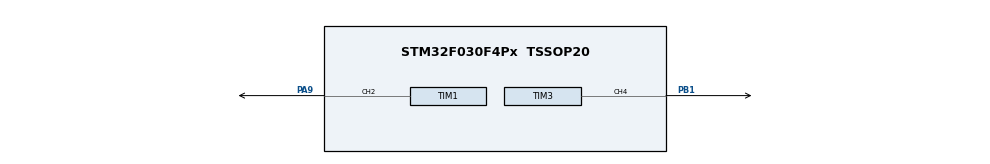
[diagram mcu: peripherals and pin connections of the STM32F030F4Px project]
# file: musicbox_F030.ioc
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Mcu.Family=STM32F0
Mcu.Name=STM32F030F4Px
Mcu.Package=TSSOP20
PA9.Signal=S_TIM1_CH2
PB1.Signal=S_TIM3_CH4
ProjectManager.HeapSize=0x200
ProjectManager.StackSize=0x400
ProjectManager.TargetToolchain=STM32CubeIDE
SH.S_TIM1_CH2.0=TIM1_CH2,PWM Generation2 CH2
SH.S_TIM3_CH4.0=TIM3_CH4,PWM Generation4 CH4
TIM1.Channel-PWM\ Generation2\ CH2=TIM_CHANNEL_2
TIM1.Period=2271
TIM1.Prescaler=7
TIM1.Pulse-PWM\ Generation2\ CH2=1136
TIM3.Channel-PWM\ Generation4\ CH4=TIM_CHANNEL_4
TIM3.Period=2271
TIM3.Prescaler=7
TIM3.Pulse-PWM\ Generation4\ CH4=1136
board=custom

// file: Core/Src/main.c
/* USER CODE BEGIN Header */
/**
  ******************************************************************************
  * @file           : main.c
  * @brief          : Main program body
  ******************************************************************************
  * @attention
  *
  * <h2><center>&copy; Copyright (c) 2021 STMicroelectronics.
  * All rights reserved.</center></h2>
  *
  * This software component is licensed by ST under BSD 3-Clause license,
  * the "License"; You may not use this file except in compliance with the
  * License. You may obtain a copy of the License at:
  *                        opensource.org/licenses/BSD-3-Clause
  *
  ******************************************************************************
  */
/* USER CODE END Header */
#include "main.h"

/* USER CODE BEGIN Includes */
#include <musicbox.hpp>
/* USER CODE END Includes */

TIM_HandleTypeDef htim1;
TIM_HandleTypeDef htim3;

void SystemClock_Config(void);
static void MX_GPIO_Init(void);
static void MX_TIM1_Init(void);
static void MX_TIM3_Init(void);

int main(void)
{

  /* MCU Configuration--------------------------------------------------------*/

  /* Reset of all peripherals, Initializes the Flash interface and the Systick. */
  HAL_Init();

  /* Configure the system clock */
  SystemClock_Config();

  /* Initialize all configured peripherals */
  MX_GPIO_Init();
  MX_TIM1_Init();
  MX_TIM3_Init();
  /* USER CODE BEGIN 2 */
  startMusic(&htim1, TIM_CHANNEL_2, &htim3, TIM_CHANNEL_4);
  /* USER CODE END 2 */

  /* Infinite loop */
  while (1)
  {

  }
}

void SystemClock_Config(void)
{
  RCC_OscInitTypeDef RCC_OscInitStruct = {0};
  RCC_ClkInitTypeDef RCC_ClkInitStruct = {0};

  /** Initializes the RCC Oscillators according to the specified parameters
  * in the RCC_OscInitTypeDef structure.
  */
  RCC_OscInitStruct.OscillatorType = RCC_OSCILLATORTYPE_HSI;
  RCC_OscInitStruct.HSIState = RCC_HSI_ON;
  RCC_OscInitStruct.HSICalibrationValue = RCC_HSICALIBRATION_DEFAULT;
  RCC_OscInitStruct.PLL.PLLState = RCC_PLL_NONE;
  if (HAL_RCC_OscConfig(&RCC_OscInitStruct) != HAL_OK)
  {
    Error_Handler();
  }
  /** Initializes the CPU, AHB and APB buses clocks
  */
  RCC_ClkInitStruct.ClockType = RCC_CLOCKTYPE_HCLK|RCC_CLOCKTYPE_SYSCLK
                              |RCC_CLOCKTYPE_PCLK1;
  RCC_ClkInitStruct.SYSCLKSource = RCC_SYSCLKSOURCE_HSI;
  RCC_ClkInitStruct.AHBCLKDivider = RCC_SYSCLK_DIV1;
  RCC_ClkInitStruct.APB1CLKDivider = RCC_HCLK_DIV1;

  if (HAL_RCC_ClockConfig(&RCC_ClkInitStruct, FLASH_LATENCY_0) != HAL_OK)
  {
    Error_Handler();
  }
}

static void MX_TIM1_Init(void)
{

  TIM_MasterConfigTypeDef sMasterConfig = {0};
  TIM_OC_InitTypeDef sConfigOC = {0};
  TIM_BreakDeadTimeConfigTypeDef sBreakDeadTimeConfig = {0};

  htim1.Instance = TIM1;
  htim1.Init.Prescaler = 7;
  htim1.Init.CounterMode = TIM_COUNTERMODE_UP;
  htim1.Init.Period = 2271;
  htim1.Init.ClockDivision = TIM_CLOCKDIVISION_DIV1;
  htim1.Init.RepetitionCounter = 0;
  htim1.Init.AutoReloadPreload = TIM_AUTORELOAD_PRELOAD_DISABLE;
  if (HAL_TIM_PWM_Init(&htim1) != HAL_OK)
  {
    Error_Handler();
  }
  sMasterConfig.MasterOutputTrigger = TIM_TRGO_RESET;
  sMasterConfig.MasterSlaveMode = TIM_MASTERSLAVEMODE_DISABLE;
  if (HAL_TIMEx_MasterConfigSynchronization(&htim1, &sMasterConfig) != HAL_OK)
  {
    Error_Handler();
  }
  sConfigOC.OCMode = TIM_OCMODE_PWM1;
  sConfigOC.Pulse = 1136;
  sConfigOC.OCPolarity = TIM_OCPOLARITY_HIGH;
  sConfigOC.OCNPolarity = TIM_OCNPOLARITY_HIGH;
  sConfigOC.OCFastMode = TIM_OCFAST_DISABLE;
  sConfigOC.OCIdleState = TIM_OCIDLESTATE_RESET;
  sConfigOC.OCNIdleState = TIM_OCNIDLESTATE_RESET;
  if (HAL_TIM_PWM_ConfigChannel(&htim1, &sConfigOC, TIM_CHANNEL_2) != HAL_OK)
  {
    Error_Handler();
  }
  sBreakDeadTimeConfig.OffStateRunMode = TIM_OSSR_DISABLE;
  sBreakDeadTimeConfig.OffStateIDLEMode = TIM_OSSI_DISABLE;
  sBreakDeadTimeConfig.LockLevel = TIM_LOCKLEVEL_OFF;
  sBreakDeadTimeConfig.DeadTime = 0;
  sBreakDeadTimeConfig.BreakState = TIM_BREAK_DISABLE;
  sBreakDeadTimeConfig.BreakPolarity = TIM_BREAKPOLARITY_HIGH;
  sBreakDeadTimeConfig.AutomaticOutput = TIM_AUTOMATICOUTPUT_DISABLE;
  if (HAL_TIMEx_ConfigBreakDeadTime(&htim1, &sBreakDeadTimeConfig) != HAL_OK)
  {
    Error_Handler();
  }
  HAL_TIM_MspPostInit(&htim1);

}

static void MX_TIM3_Init(void)
{

  TIM_MasterConfigTypeDef sMasterConfig = {0};
  TIM_OC_InitTypeDef sConfigOC = {0};

  htim3.Instance = TIM3;
  htim3.Init.Prescaler = 7;
  htim3.Init.CounterMode = TIM_COUNTERMODE_UP;
  htim3.Init.Period = 2271;
  htim3.Init.ClockDivision = TIM_CLOCKDIVISION_DIV1;
  htim3.Init.AutoReloadPreload = TIM_AUTORELOAD_PRELOAD_DISABLE;
  if (HAL_TIM_PWM_Init(&htim3) != HAL_OK)
  {
    Error_Handler();
  }
  sMasterConfig.MasterOutputTrigger = TIM_TRGO_RESET;
  sMasterConfig.MasterSlaveMode = TIM_MASTERSLAVEMODE_DISABLE;
  if (HAL_TIMEx_MasterConfigSynchronization(&htim3, &sMasterConfig) != HAL_OK)
  {
    Error_Handler();
  }
  sConfigOC.OCMode = TIM_OCMODE_PWM1;
  sConfigOC.Pulse = 1136;
  sConfigOC.OCPolarity = TIM_OCPOLARITY_HIGH;
  sConfigOC.OCFastMode = TIM_OCFAST_DISABLE;
  if (HAL_TIM_PWM_ConfigChannel(&htim3, &sConfigOC, TIM_CHANNEL_4) != HAL_OK)
  {
    Error_Handler();
  }
  HAL_TIM_MspPostInit(&htim3);

}

static void MX_GPIO_Init(void)
{

  /* GPIO Ports Clock Enable */
  __HAL_RCC_GPIOB_CLK_ENABLE();
  __HAL_RCC_GPIOA_CLK_ENABLE();

}

void Error_Handler(void)
{
  __disable_irq();
  while (1)
  {
  }
}

/************************ (C) COPYRIGHT STMicroelectronics *****END OF FILE****/
